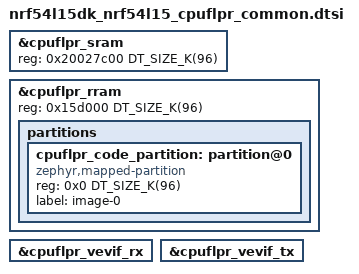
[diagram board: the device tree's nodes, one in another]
/*
 * Copyright (c) 2026 Nordic Semiconductor ASA
 *
 * SPDX-License-Identifier: Apache-2.0
 */

&cpuflpr_sram {
	reg = <0x20027c00 DT_SIZE_K(96)>;
	ranges = <0x0 0x20027c00 DT_SIZE_K(96)>;
};

&cpuflpr_rram {
	reg = <0x15d000 DT_SIZE_K(96)>;
	ranges = <0x0 0x15d000 DT_SIZE_K(96)>;

	partitions {
		ranges;
		#address-cells = <1>;
		#size-cells = <1>;

		cpuflpr_code_partition: partition@0 {
			compatible = "zephyr,mapped-partition";
			reg = <0x0 DT_SIZE_K(96)>;
			label = "image-0";
		};
	};
};

&cpuflpr_vevif_rx {
	status = "okay";
};

&cpuflpr_vevif_tx {
	status = "okay";
};
